# nrf54ls05a_application register map
Vendor: Nordic Semiconductor; Series: nrf54l; File version: 1
CPU: CM33 r0p4, little endian, MPU, no FPU, 3 interrupt priority bits, 270 interrupts
Registers are 32-bit, read-write, reset 0x0 unless marked. A register's access mark holds for its fields unless they carry their own. Offsets are from the block's base; [hi:lo] are bit positions; lines under a group give offsets from that group; {n}, {i} and the like mark numbered series; 'fields as' and 'values as' point back to an identical list.

## GLOBAL_P1 — GPIO Port 0
Base 0x400D8200
Same registers: GLOBAL_P0 0x4010A000
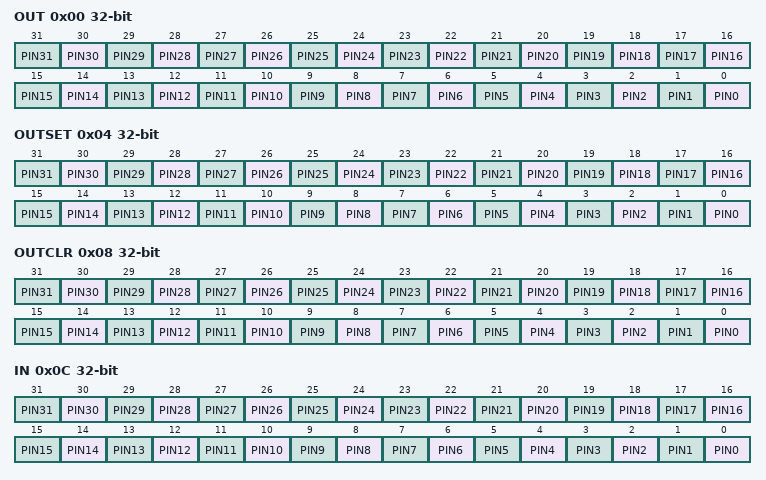
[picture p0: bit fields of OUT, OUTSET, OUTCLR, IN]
0x00 OUT — Write GPIO port
  [all] fields
    0=Low (Pin driver is low); 1=High (Pin driver is high)
  [n] PIN{n} (n=0..31)
0x04 OUTSET write-1-sets — Set individual bits in GPIO port
  [all] fields
    on read: 0=Low (Read: pin driver is low); 1=High (Read: pin driver is high) | on write: 1=Set (Write: writing a '1' sets the pin high; writing a '0' has no effect)
  [n] PIN{n} (n=0..31)
0x08 OUTCLR write-1-clears — Clear individual bits in GPIO port
  [all] fields
    on read: 0=Low (Read: pin driver is low); 1=High (Read: pin driver is high) | on write: 1=Clear (Write: writing a '1' sets the pin low; writing a '0' has no effect)
  [n] PIN{n} (n=0..31)
0x0C IN ro — Read GPIO port
  [all] fields
    0=Low (Pin input is low); 1=High (Pin input is high)
  [n] PIN{n} (n=0..31)
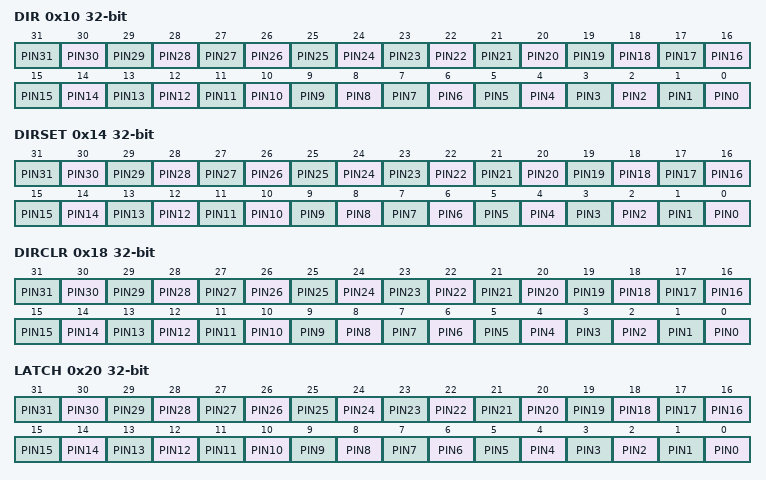
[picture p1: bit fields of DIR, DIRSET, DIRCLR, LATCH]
0x10 DIR — Direction of GPIO pins
  [all] fields
    0=Input (Pin set as input); 1=Output (Pin set as output)
  [n] PIN{n} (n=0..31)
0x14 DIRSET write-1-sets
  [all] fields
    on read: 0=Input (Read: pin set as input); 1=Output (Read: pin set as output) | on write: 1=Set (Write: writing a '1' sets pin to output; writing a '0' has no effect)
  [n] PIN{n} (n=0..31) — Set as output pin {n}
0x18 DIRCLR write-1-clears — DIR clear register
  [all] fields
    on read: 0=Input (Read: pin set as input); 1=Output (Read: pin set as output) | on write: 1=Clear (Write: writing a '1' sets pin to input; writing a '0' has no effect)
  [n] PIN{n} (n=0..31) — Set as input pin {n}
0x20 LATCH — Latch register indicating what GPIO pins that have met the criteria set in the PIN_CNF[n].SENSE registers
  [all] fields
    0=NotLatched (Criteria has not been met); 1=Latched (Criteria has been met)
  [n] PIN{n} (n=0..31) — Status on whether PIN{n} has met criteria set in PIN_CNF[{n}].SENSE register. Write '1' to clear.
0x24 DETECTMODE — Select between default DETECT signal behavior and LDETECT mode
  [0] DETECTMODE
    0=Default (DETECT directly connected to PIN DETECT signals); 1=LDETECT (Use the latched LDETECT behavior)
0x30 PORTCNF group — Unspecified
  0x00 WEAKPU — Control global weak pull-ups on the selected set of GPIO pins
    [1:0] PULLUP — Control pull-up.
      0=Disabled (Pull-up is disabled.); 1=PU0 (Enable pull-up 0.); 2=PU1 (Enable pull-up 1.); 3=PU2 (Enable pull-up 2.)
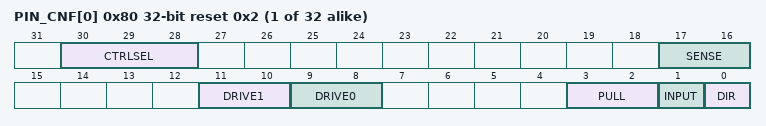
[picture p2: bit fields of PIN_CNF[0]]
{0x80+4i} PIN_CNF[{i}] (i=0..31) reset 0x2 — Description collection: Pin n configuration of GPIO pin
  [30:28] CTRLSEL — Select which module has direct control over this pin
    0=GPIO (GPIO or peripherals with PSEL registers); 1=VPR (VPR processor); 4=GRTC (GRTC peripheral)
  [17:16] SENSE — Pin sensing mechanism
    0=Disabled; 2=High (Sense for high level); 3=Low (Sense for low level)
  [11:10] DRIVE1 — Drive configuration for '1'
    0=S1 (Standard '1'); 1=H1 (High drive '1'); 2=D1 (Disconnect '1'(normally used for wired-or connections)); 3=E1 (Extra high drive '1')
  [9:8] DRIVE0 — Drive configuration for '0'
    0=S0 (Standard '0'); 1=H0 (High drive '0'); 2=D0 (Disconnect '0'(normally used for wired-or connections)); 3=E0 (Extra high drive '0')
  [3:2] PULL — Pull configuration
    0=Disabled (No pull); 1=Pull-down on pin; 3=Pull-up on pin
  [1] INPUT — Connect or disconnect input buffer
    0=Connect input buffer; 1=Disconnect input buffer
  [0] DIR — Pin direction. Same physical register as DIR register
    0=Input (Configure pin as an input pin); 1=Output (Configure pin as an output pin)

## GLOBAL_POWER — Power control
Base 0x4010E000; alternate view of GLOBAL_CLOCK
0x30 TASKS_CONSTLAT wo — Enable Constant Latency mode
  [0] TASKS_CONSTLAT
    1=Trigger task
0x34 TASKS_LOWPWR wo — Enable Low-power mode (variable latency)
  [0] TASKS_LOWPWR
    1=Trigger task
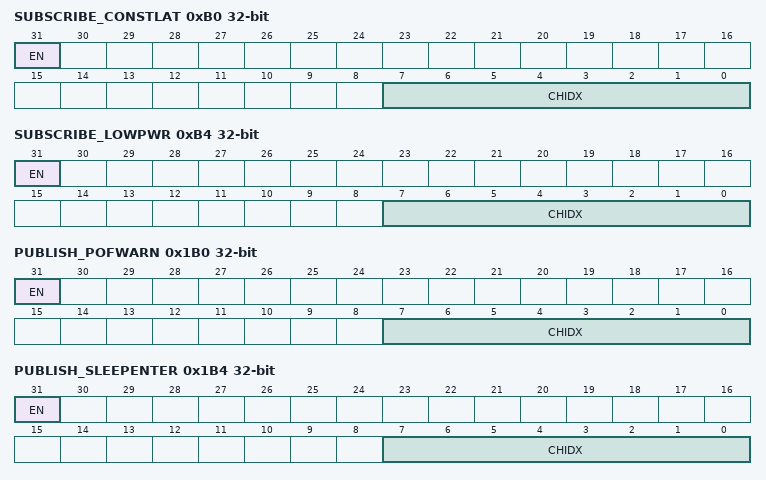
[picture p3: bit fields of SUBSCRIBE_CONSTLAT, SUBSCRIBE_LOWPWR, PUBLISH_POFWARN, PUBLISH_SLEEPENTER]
0xB0 SUBSCRIBE_CONSTLAT — Subscribe configuration for task CONSTLAT
  [31] EN
    0=Disabled (Disable subscription); 1=Enabled (Enable subscription)
  [7:0] CHIDX — DPPI channel that task CONSTLAT will subscribe to
0xB4 SUBSCRIBE_LOWPWR — Subscribe configuration for task LOWPWR
  [31] EN
    values as SUBSCRIBE_CONSTLAT.EN
  [7:0] CHIDX — DPPI channel that task LOWPWR will subscribe to
0x130 EVENTS_POFWARN — Power failure warning
  [0] EVENTS_POFWARN
    0=NotGenerated (Event not generated); 1=Generated (Event generated)
0x134 EVENTS_SLEEPENTER — CPU entered WFI/WFE sleep
  [0] EVENTS_SLEEPENTER
    values as EVENTS_POFWARN.EVENTS_POFWARN
0x138 EVENTS_SLEEPEXIT — CPU exited WFI/WFE sleep
  [0] EVENTS_SLEEPEXIT
    values as EVENTS_POFWARN.EVENTS_POFWARN
0x1B0 PUBLISH_POFWARN — Publish configuration for event POFWARN
  [31] EN
    0=Disabled (Disable publishing); 1=Enabled (Enable publishing)
  [7:0] CHIDX — DPPI channel that event POFWARN will publish to
0x1B4 PUBLISH_SLEEPENTER — Publish configuration for event SLEEPENTER
  [31] EN
    values as PUBLISH_POFWARN.EN
  [7:0] CHIDX — DPPI channel that event SLEEPENTER will publish to
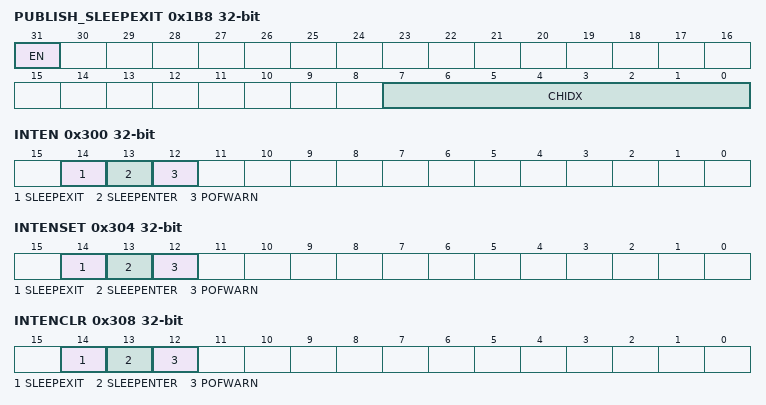
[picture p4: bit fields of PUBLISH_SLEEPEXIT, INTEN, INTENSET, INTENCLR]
0x1B8 PUBLISH_SLEEPEXIT — Publish configuration for event SLEEPEXIT
  [31] EN
    values as PUBLISH_POFWARN.EN
  [7:0] CHIDX — DPPI channel that event SLEEPEXIT will publish to
0x300 INTEN — Enable or disable interrupt
  [all] fields
    0=Disabled; 1=Enabled
  [14] SLEEPEXIT — Enable or disable interrupt for event SLEEPEXIT
  [13] SLEEPENTER — Enable or disable interrupt for event SLEEPENTER
  [12] POFWARN — Enable or disable interrupt for event POFWARN
0x304 INTENSET — Enable interrupt
  [all] fields
    on read: 0=Disabled (Read: Disabled); 1=Enabled (Read: Enabled) | on write: 1=Set (Enable)
  [14] SLEEPEXIT write-1-sets — Write '1' to enable interrupt for event SLEEPEXIT
  [13] SLEEPENTER write-1-sets — Write '1' to enable interrupt for event SLEEPENTER
  [12] POFWARN write-1-sets — Write '1' to enable interrupt for event POFWARN
0x308 INTENCLR — Disable interrupt
  [all] fields
    on read: 0=Disabled (Read: Disabled); 1=Enabled (Read: Enabled) | on write: 1=Clear (Disable)
  [14] SLEEPEXIT write-1-clears — Write '1' to disable interrupt for event SLEEPEXIT
  [13] SLEEPENTER write-1-clears — Write '1' to disable interrupt for event SLEEPENTER
  [12] POFWARN write-1-clears — Write '1' to disable interrupt for event POFWARN
{0x500+4i} GPREGRET[{i}] (i=0..1) — Description collection: General purpose retention register
  [7:0] GPREGRET — General purpose retention register
0x520 CONSTLATSTAT ro — Status of constant latency
  [0] STATUS
    0=Disable (Constant latency disabled); 1=Enable (Constant latency enabled)

## Notices in the file
Copyright (c) 2010 - 2026, Nordic Semiconductor ASA All rights reserved.
SPDX-License-Identifier: BSD-3-Clause
Redistribution and use in source and binary forms, with or without
modification, are permitted provided that the following conditions are met:
1. Redistributions of source code must retain the above copyright notice, this
list of conditions and the following disclaimer.
2. Redistributions in binary form must reproduce the above copyright
notice, this list of conditions and the following disclaimer in the
documentation and/or other materials provided with the distribution.
3. Neither the name of Nordic Semiconductor ASA nor the names of its
contributors may be used to endorse or promote products derived from this
software without specific prior written permission.
THIS SOFTWARE IS PROVIDED BY THE COPYRIGHT HOLDERS AND CONTRIBUTORS "AS IS"
AND ANY EXPRESS OR IMPLIED WARRANTIES, INCLUDING, BUT NOT LIMITED TO, THE
IMPLIED WARRANTIES OF MERCHANTABILITY, AND FITNESS FOR A PARTICULAR PURPOSE
ARE DISCLAIMED. IN NO EVENT SHALL NORDIC SEMICONDUCTOR ASA OR CONTRIBUTORS BE
LIABLE FOR ANY DIRECT, INDIRECT, INCIDENTAL, SPECIAL, EXEMPLARY, OR
CONSEQUENTIAL DAMAGES (INCLUDING, BUT NOT LIMITED TO, PROCUREMENT OF
SUBSTITUTE GOODS OR SERVICES; LOSS OF USE, DATA, OR PROFITS; OR BUSINESS
INTERRUPTION) HOWEVER CAUSED AND ON ANY THEORY OF LIABILITY, WHETHER IN
CONTRACT, STRICT LIABILITY, OR TORT (INCLUDING NEGLIGENCE OR OTHERWISE)
ARISING IN ANY WAY OUT OF THE USE OF THIS SOFTWARE, EVEN IF ADVISED OF THE
POSSIBILITY OF SUCH DAMAGE.
